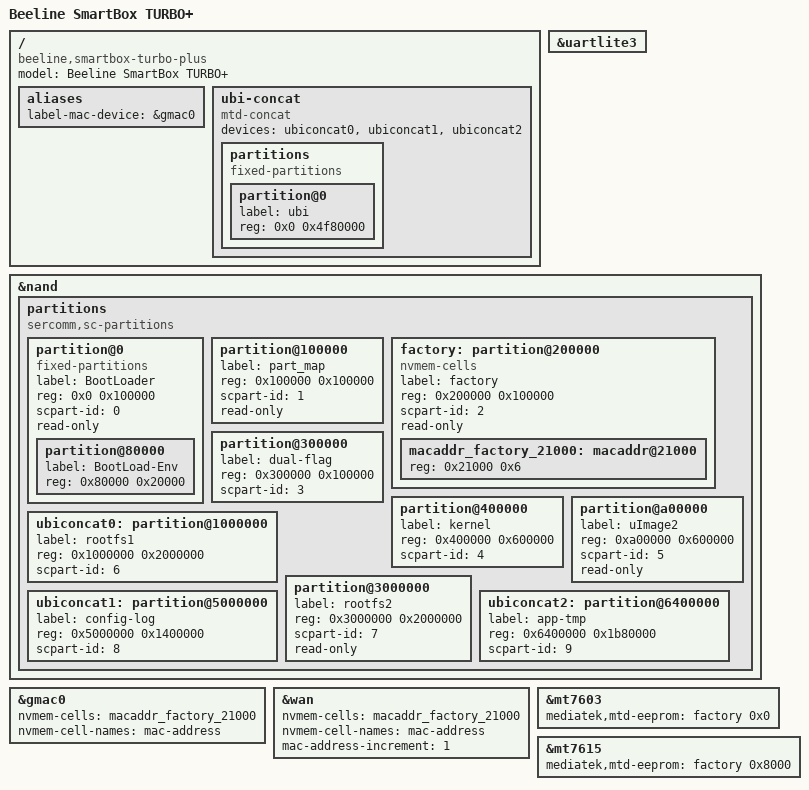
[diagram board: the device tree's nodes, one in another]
// SPDX-License-Identifier: GPL-2.0-or-later OR MIT

#include "mt7621_sercomm_s3.dtsi"

/ {
	compatible = "beeline,smartbox-turbo-plus", "mediatek,mt7621-soc";
	model = "Beeline SmartBox TURBO+";

	aliases {
		label-mac-device = &gmac0;
	};

	ubi-concat {
		compatible = "mtd-concat";
		devices = <&ubiconcat0 &ubiconcat1 &ubiconcat2>;

		partitions {
			compatible = "fixed-partitions";
			#address-cells = <1>;
			#size-cells = <1>;

			partition@0 {
				label = "ubi";
				reg = <0x0 0x4f80000>;
			};
		};
	};
};

&uartlite3 { // ZigBee
	status = "okay";
};

&nand {
	status = "okay";

	partitions {
		compatible = "sercomm,sc-partitions", "fixed-partitions";
		#address-cells = <1>;
		#size-cells = <1>;

		partition@0 {
			label = "BootLoader";
			reg = <0x0 0x100000>;
			scpart-id = <0>;
			read-only;

			compatible = "fixed-partitions";
			#address-cells = <1>;
			#size-cells = <1>;

			partition@80000 {
				label = "BootLoad-Env";
				reg = <0x80000 0x20000>;
			};

		};

		partition@100000 {
			label = "part_map";
			reg = <0x100000 0x100000>;
			scpart-id = <1>;
			read-only;
		};

		factory: partition@200000 {
			label = "factory";
			reg = <0x200000 0x100000>;
			scpart-id = <2>;
			read-only;

			compatible = "nvmem-cells";
			#address-cells = <1>;
			#size-cells = <1>;

			macaddr_factory_21000: macaddr@21000 {
				reg = <0x21000 0x6>;
			};
		};

		partition@300000 {
			label = "dual-flag";
			reg = <0x300000 0x100000>;
			scpart-id = <3>;
		};

		partition@400000 {
			label = "kernel";
			reg = <0x400000 0x600000>;
			scpart-id = <4>;
		};

		partition@a00000 {
			label = "uImage2";
			reg = <0xa00000 0x600000>;
			scpart-id = <5>;
			read-only;
		};

		ubiconcat0: partition@1000000 {
			label = "rootfs1";
			reg = <0x1000000 0x2000000>;
			scpart-id = <6>;
		};

		partition@3000000 {
			label = "rootfs2";
			reg = <0x3000000 0x2000000>;
			scpart-id = <7>;
			read-only;
		};

		ubiconcat1: partition@5000000 {
			label = "config-log";
			reg = <0x5000000 0x1400000>;
			scpart-id = <8>;
		};

		ubiconcat2: partition@6400000 {
			label = "app-tmp";
			reg = <0x6400000 0x1b80000>;
			scpart-id = <9>;
		};

		/*
		 * 512 KiB Bad Block Table
		 * 0x8000000-0x7f80000=0x80000
		 */
	};
};

&gmac0 {
	nvmem-cells = <&macaddr_factory_21000>;
	nvmem-cell-names = "mac-address";
};

&wan {
	nvmem-cells = <&macaddr_factory_21000>;
	nvmem-cell-names = "mac-address";
	mac-address-increment = <1>;
};

&mt7603 {
	mediatek,mtd-eeprom = <&factory 0x0>;
};

&mt7615 {
	mediatek,mtd-eeprom = <&factory 0x8000>;
};
